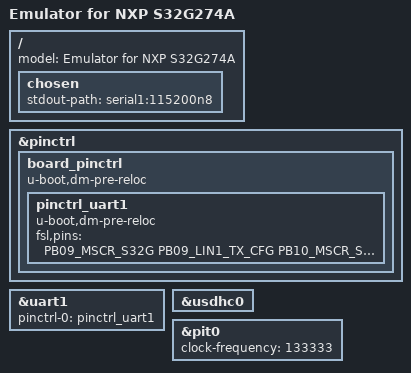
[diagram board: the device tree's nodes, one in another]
// SPDX-License-Identifier: (GPL-2.0+ OR BSD-3-Clause)
/*
 * Copyright 2021-2022 NXP
 */

/dts-v1/;
#include <dt-bindings/pinctrl/s32g-pinctrl.h>
#include "s32g2.dtsi"

/ {
	model = "Emulator for NXP S32G274A";

	chosen {
		stdout-path = "serial1:115200n8";
	};
};

&pinctrl {
	board_pinctrl {
		u-boot,dm-pre-reloc;
		pinctrl_uart1: pinctrl_uart1 {
			u-boot,dm-pre-reloc;
			fsl,pins = <PB09_MSCR_S32G PB09_LIN1_TX_CFG
				    PB10_MSCR_S32G PB10_LIN1_RX_CFG
				    LIN1_RX_IMCR PB10_LIN1_RX_IN
				    >;
		};
	};
};

&uart1{
	pinctrl-0 = <&pinctrl_uart1>;
	pinctrl-names = "default";
	status = "okay";
};

&usdhc0 {
	status = "okay";
};

&pit0 {
	/delete-property/ clocks;
	/delete-property/ clock-names;
	/**
	 * Artificially reduce the frequency to 1/10 of the real rate
	 * to increase responsiveness
	 */
	clock-frequency = <133333>;
};
